# UFS0_P2A_WRAP_CFG_VBP_UFSHCI register map
Vendor: Texas Instruments
Peripheral module from a debugger description file (folder J7ES).
Registers are 32-bit, read-only, reset 0x0 unless marked. A register's access mark holds for its fields unless they carry their own. Offsets are as the file gives them; lines under a group give offsets from that group; [hi:lo] are bit positions; {n}, {i} and the like mark numbered series; 'fields as' and 'values as' point back to an identical list; <NAME> marks a mode.

## UFS0_P2A_WRAP_CFG_VBP_UFSHCI
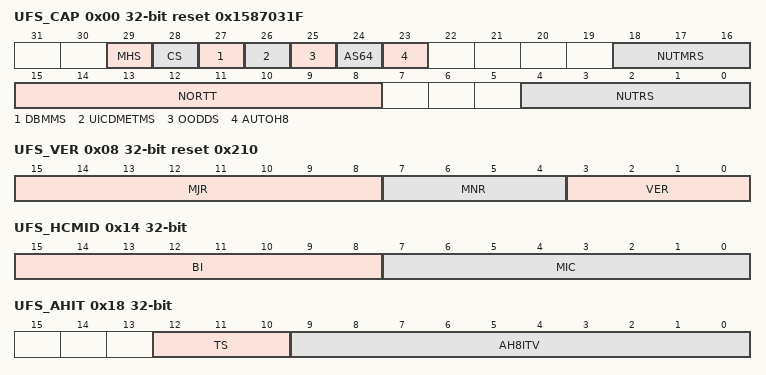
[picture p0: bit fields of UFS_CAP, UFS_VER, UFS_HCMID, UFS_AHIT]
0x00 UFS_CAP reset 0x1587031F — Host Controller Capabilities Register This register describes the basic capabilities of the UFS host controller.
  [29] MHS — Multi-Host Support
  [28] CS — Crypto Support
  [27] DBMMS — Device Bus Master Mode Supported (Unified Memory (UM) UFSHCI Only)
  [26] UICDMETMS — UIC DME_TEST_MODE Command Supported
  [25] OODDS — Out of Order Data Delivery Supported
  [24] AS64 — 64-bit Addressing Supported
  [23] AUTOH8 — Auto-Hibernation Support
  [18:16] NUTMRS — Number of UTP Task Management Request Slots
  [15:8] NORTT — Number of Pending RTTs supported
  [4:0] NUTRS — Number of UTP Transfer Request Slots
0x08 UFS_VER reset 0x210 — UFS Version Register This register indicates the major and minor version of the UFSHCI specification that the controller implementation supports. The upper two bytes represent the major version number, and the lower two bytes represent the minor version number.
  [15:8] MJR — Major Version Number
  [7:4] MNR — Minor Version Number
  [3:0] VER — Version Suffix (VS)
0x10 UFS_HCPID — Host Controller Identification Descriptor Register (Device ID and Device Class) This register indicates the product identification information for host controller.
  [31:0] PID — Product ID
0x14 UFS_HCMID — Host Controller Identification Descriptor Register (Product ID and Manufacturer ID) This register provides Manufacturer identification information for host controller manufacturer. The Manufacturer ID is defined by JEDEC in Standard Manufacturer's identification code (JEDEC-JEP106). The Manufacturer ID consists of two parts: Manufacturer Identification Code and Bank Index.
  [15:8] BI — Bank Index
  [7:0] MIC — Manufacturer Identification Code
0x18 UFS_AHIT access per field — Auto-Hibernate Idle Timer Register The UFS utilizes UniPro and SCSI standards as its power management framework. To improve power efficiency, the UFS host controller may support a mechanism called auto-hibernation. Auto-hibernation allows the host controller to put the UFS link into HIBERN8 state autonomously. The [23] AUTOH8 bit provides a method for software to detect support of this feature. The [9-0] AH8ITV bit filed together with the [12-10] TS bit filed provides a method for software to directly control of this feature. Note: Additionally to the above conditions, the auto-hibernation counter checks the status of the UniPro protocol layer. The host controller will only enter hibernate state when there is no pending UniPro communication.
  [12:10] TS rw — Time Scale
  [9:0] AH8ITV rw — Auto-Hibernate Idle Timer Value
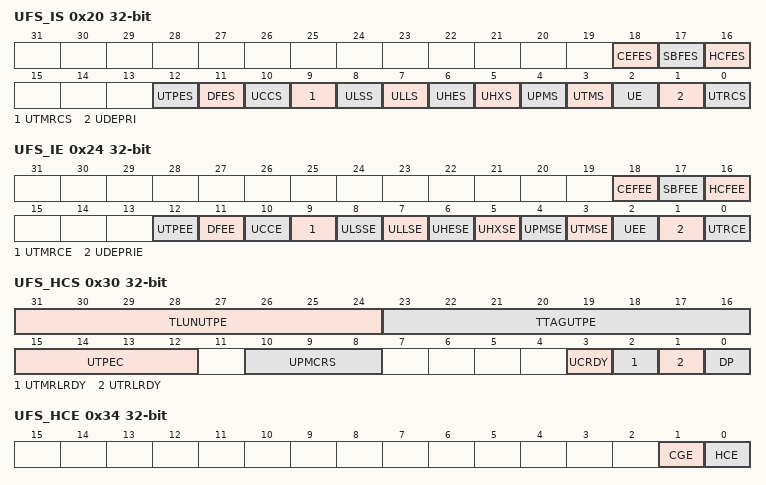
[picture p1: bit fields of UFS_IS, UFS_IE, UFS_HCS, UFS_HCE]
0x20 UFS_IS access not given — Interrupt Status Register This register indicates pending interrupts that require service by the low level driver firmware.
  [18] CEFES — Crypto Engine Fatal Error Status (access RW1C)
  [17] SBFES — System Bus Fatal Error Status (access RW1C)
  [16] HCFES — Host Controller Fatal Error Status (access RW1C)
  [12] UTPES — UTP Error Status (access RW1C)
  [11] DFES — Device Fatal Error Status (access RW1C)
  [10] UCCS — UIC Command Completion Status (access RW1C)
  [9] UTMRCS — UTP Task Management Request Completion Status (access RW1C)
  [8] ULSS — UIC Link Startup Status (access RW1C)
  [7] ULLS — UIC Link Lost Status (access RW1C)
  [6] UHES — UIC Hibernate Enter Status (access RW1C)
  [5] UHXS — UIC Hibernate Exit Status (access RW1C)
  [4] UPMS — UIC Power Mode Status (access RW1C)
  [3] UTMS — UIC Test Mode Status (access RW1C)
  [2] UE — UIC Error (access RW1C)
  [1] UDEPRI — UIC DME_ENDPOINTRESET Indication (access RW1C)
  [0] UTRCS — UTP Transfer Request Completion Status (access RW1C)
0x24 UFS_IE access per field — Interrupt Enable Register This register enables and disables the reporting of the corresponding interrupt to host software. When a bit is set (1h) and the corresponding interrupt condition is active, then an interrupt is generated. Interrupt sources that are disabled (0h) are still indicated in the register. The register bit assignment matches with the register.
  [18] CEFEE rw — Crypto Engine Fatal Error Enable
  [17] SBFEE rw — System Bus Fatal Error Enable
  [16] HCFEE rw — Host Controller Fatal Error Enable
  [12] UTPEE rw — UTP Error Enable
  [11] DFEE rw — Device Fatal Error Enable
  [10] UCCE rw — UIC COMMAND Completion Enable
  [9] UTMRCE rw — UTP Task Management Request Completion Enable
  [8] ULSSE rw — UIC Link Startup Status Enable
  [7] ULLSE rw — UIC Link Lost Status Enable
  [6] UHESE rw — UIC Hibernate Enter Status Enable
  [5] UHXSE rw — UIC Hibernate Exit Status Enable
  [4] UPMSE rw — UIC Power Mode Status Enable
  [3] UTMSE rw — UIC Test Mode Status Enable
  [2] UEE rw — UIC Error Enable
  [1] UDEPRIE rw — UIC DME_ENDPOINTRESET
  [0] UTRCE rw — UTP Transfer Request Completion Enable
0x30 UFS_HCS — Host Controller Status Register The software shall check that the [2] UTMRLRDY bit is set to 1h before issuing a Task Management command. The software shall check that the [1] UTRLRDY bit is set to 1h before issuing an UTP command. The prerequisite to send any DME command is that the [0] HCE and [3] UCRDY bits are set to 1h. The hardware does not check nor restrict the usage of any UIC command. Sending the DME_ENABLE UIC command is not permitted. Additional UIC command specific prerequisites: DME cmd = DME_SET, DP = Don't care, UIC state = Don't care DME cmd = DME_GET, DP = Don't care, UIC state = Don't care DME cmd = DME_PEER_SET, DP = 1, UIC state = LinkUp DME cmd = DME_PEER_GET, DP = 1, UIC state = LinkUp DME cmd = DME_RESET, DP = Don't care, UIC state = Don't care DME cmd = DME_ENPOINTRESET, DP = 1, UIC state = LinkUp DME cmd = DME_LINKSTARTUP, DP = 0, UIC state = LinkDown DME cmd = DME_HIBERNATE_ENTER, DP = Don't care, UIC state = LinkUp, LinkDown DME cmd = DME_HIBERNATE_EXIT, DP = 0, UIC state = Hibernate
  [31:24] TLUNUTPE — Target LUN of UTP Error
  [23:16] TTAGUTPE — Task Tag of UTP Error
  [15:12] UTPEC — UTP Error Code
  [10:8] UPMCRS — UIC Power Mode Change Request Status
  [3] UCRDY — UIC COMMAND Ready
  [2] UTMRLRDY — UTP Task Management Request List Ready
  [1] UTRLRDY — UTP Transfer Request List Ready
  [0] DP — Device Present
0x34 UFS_HCE access per field — Host Controller Enable Register
  [1] CGE rw — Crypto General Enable
  [0] HCE rw — Host Controller Enable
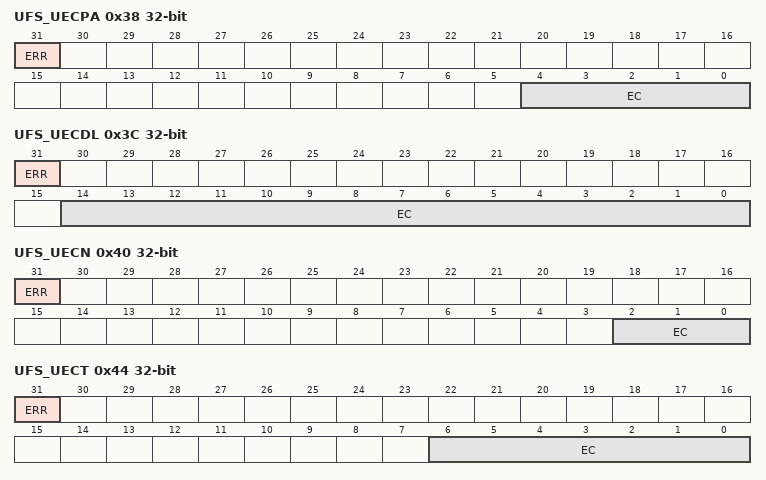
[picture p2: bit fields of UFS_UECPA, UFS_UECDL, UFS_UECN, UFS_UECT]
0x38 UFS_UECPA — Host Controller UIC Error Code PHY Adapter Layer Register Note: The register content is automatically cleared after reading.
  [31] ERR — UIC PHY Adapter Layer Error
  [4:0] EC — UIC Adapter Layer Error
0x3C UFS_UECDL — Host UIC Error Code Data Link Layer Register Note: The register content is automatically cleared after reading.
  [31] ERR — UIC Data Link Layer Error
  [14:0] EC — UIC Data Link Layer Error
0x40 UFS_UECN — Host UIC Error Code Network Layer Register Note: The register content is automatically cleared after reading.
  [31] ERR — UIC Network Layer Error
  [2:0] EC — UIC Network Layer Error Code
0x44 UFS_UECT — Host UIC Error Code Transport Layer Register Note: The register content is automatically cleared after reading.
  [31] ERR — UIC Transport Layer Error
  [6:0] EC — UIC Transport Layer Error Code
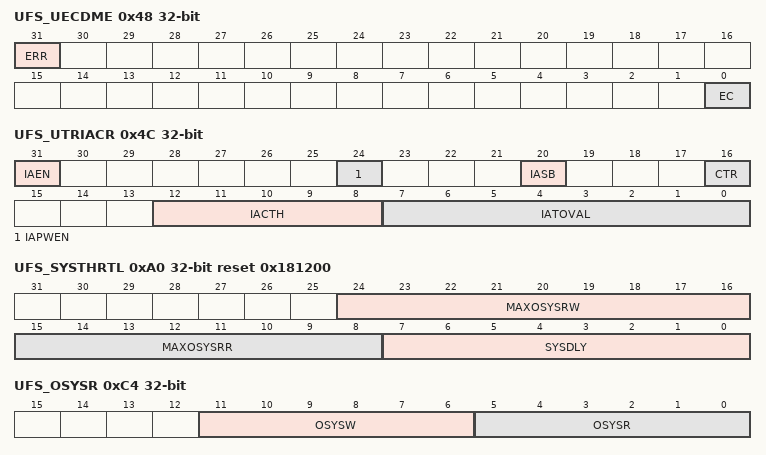
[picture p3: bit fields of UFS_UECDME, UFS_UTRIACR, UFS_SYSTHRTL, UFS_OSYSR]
0x48 UFS_UECDME — Host UIC Error Code DME Register The register is reserved for future use and is fixed to 0000 0000h. Note: The register content is automatically cleared after reading.
  [31] ERR — UIC DME Error
  [0] EC — UIC DME Error Code
0x4C UFS_UTRIACR access per field — UTP Transfer Request Interrupt Aggregation Control Register
  [31] IAEN rw — Interrupt Aggregation Enable/Disable
  [24] IAPWEN rw — Interrupt Aggregation Parameter Write Enable
  [20] IASB ro — Interrupt Aggregation Status Bit
  [16] CTR wo — Counter and Timer Reset
  [12:8] IACTH rw — Interrupt Aggregation Counter Threshold
  [7:0] IATOVAL rw — Interrupt Aggregation Timeout Value
0x50 UFS_UTRLBA access per field — UTP Transfer Request List Base Address Register
  [31:10] UTRLBA rw — UTP Transfer Request List Base Address
0x54 UFS_UTRLBAU rw — UTP Transfer Request List Base Address Upper 32-bits Register Note: Since this UFS host controller implementation supports an 32-bit address bus, the upper 32-bit of the base address are ignored.
  [31:0] UTRLBAU — UTP Transfer Request List Base Address Upper
0x58 UFS_UTRLDBR access not given — UTP Transfer Request List Door Bell Register This register controls the basic actions of the host controller.
  [31:0] UTRLDBR — UTP Transfer Request List Door Bell Register (access RW1S)
0x5C UFS_UTRLCLR wo — UTP Transfer Request List Clear Register
  [31:0] UTRLCLR — UTP Transfer Request List Clear
0x60 UFS_UTRLRSR access per field — UTP Transfer Request List Run Stop Register This register controls the command processing of the UFS host controller.
  [0] UTRLRSR rw — UTP Transfer Request List Run-Stop
0x64 UFS_UTRLCNR access not given — UTP Transfer Request List Completion Notification Register
  [31:0] UTRLCNR — UTP Transfer Request List Completion Notification Register (access RW1C)
0x70 UFS_UTMRLBA access per field — UTP Task Management Request List Base Address
  [31:10] UTMRLBA rw
0x74 UFS_UTMRLBAU rw — UTP Task Management Request List Base Address Upper 32-bits Register Note: This register is only used when the host is configured to use a 64-bit address bus.
  [31:0] UTMRLBAU — UTP Task Management Request List Base Address
0x78 UFS_UTMRLDBR access not given — UTP Task Management Request List Door Bell Register
  [7:0] UTMRLDBR — UTP Task Management Request List Doorbell Register (access RW1S)
0x7C UFS_UTMRLCLR access per field — UTP Task Management Request List Clear Register
  [7:0] UTMRLCLR wo — UTP Task Management List Clear Register
0x80 UFS_UTMRLRSR access per field — - UTP Task Management Request List Run Stop Register
  [0] UTMRLRSR rw — UTP Task Management Request List Run-Stop Register
0x90 UFS_UICCMD access per field — UIC Command Register Sending the DME_ENABLE UIC command is not permitted since this will be done automatically during the UFS host controller initialization.
  [7:0] CMDOP rw — Command Opcode
0x94 UFS_UICCMDARG1 rw — UIC Command Argument 1 Register MIBattribute: Indicates the ID of the attribute of the requested. See MIPI UniPro Specification (UNIPRO) for the details of the MIBattribute parameter. GenSelectorIndex: Indicates the targeted M-PHY data lane or CPort or Test Feature when relevant. See MIPI UniPro Specification (UNIPRO) for the details of the GenSelectorIndex parameter. Layer: L1 - Valid Range: 0 to 2×PA_MaxDataLanes - 1 Layer: L4/Cport - Valid Range: 0 to T_NumCPorts - 1 Layer: L4/Test Feature - Valid Range: 0 to T_NumTestFeatures - 1 ResetLevel: Indicates the reset type. See MIPI UniPro Specification (UNIPRO) for the details of the ResetLevel parameter. 0h - Cold Reset 1h - Warm Reset 2h-FFh - Reserved
  [31:0] ARG1 — UIC Command Argument 1 (MIBattribute, GenSelectorIndex, ResetLevel)
0x98 UFS_UICCMDARG2 rw — UIC Command Argument 2 Register AttrSetType: Indicates whether the attribute value (AttrSet = NORMAL) or the attribute non-volatile reset value (STATIC) setting is requested. See MIPI UniPro Specification (UNIPRO) for the details of the AttrSetType parameter. ConfigResultCode: Indicates the result of the UIC configuration command request. It is valid after host controller has set the [10] UCCS bit to 1h. See MIPI UniPro Specification (UNIPRO) for the details of the ConfigResultCode parameter. 0h = SUCCESS 1h = INVALID_MIB_ATTRIBUTE 2h = INVALID_MIB_ATTRIBUTE_VALUE 3h = READ_ONLY_MIB_ATTRIBUTE 4h = WRITE_ONLY_MIB_ATTRIBUTE 5h = BAD_INDEX 6h = LOCKED_MIB_ATTRIBUTE 7h = BAD_TEST_FEATURE_INDEX 8h = PEER_COMMUNICATION_FAILURE 9h = BUSY Ah = DME_FAILURE Bh-FFh = Reserved GenericErrorCode: Indicates the result of the UIC control command request. It is valid after host controller has set the [10] UCCS bit to 1h. See MIPI UniPro Specification (UNIPRO) for the details of the GenericErrorCode parameter. 0h = SUCCESS 1h = FAILURE 2h-FFh = Reserved
  [31:0] ARG2 — UIC Command Argument 2 (AttrSetType, ConfigResultCode, GenericErrorCode)
0x9C UFS_UICCMDARG3 rw — UIC Command Argument 3 Register MIBvalue_R: Indicates the value of the attribute as returned by the UIC command returned. It is valid after host controller has set the [10] UCCS bit to 1h. See MIPI UniPro Specification (UNIPRO) for the details of the MIBvalue parameter. MIBvalue_W: Indicates the value of the attribute to be set. See MIPI UniPro Specification (UNIPRO) for details of the MIBvalue parameter.
  [31:0] ARG3 — Argument 3
0xA0 UFS_SYSTHRTL access per field reset 0x181200 — SYS Throttling Register In case of heavy data traffic, the UFS host controller might not leave sufficient bandwidth of the OCP/AXI fabric for other peripheral. This register allows throttling the UFS host controller either by limiting the number of outstanding read requests on the OCP/AXI bus or by specifying a minimum delay between two consecutive OCP/AXI accesses. Limiting the number of outstanding requests may also be required in case the bus fabric can only handle a limited amount of requests.
  [24:16] MAXOSYSRW rw — Max Outstanding SYS Write Requests (AXI Only)
  [15:8] MAXOSYSRR rw — Max Outstanding SYS Read Requests
  [7:0] SYSDLY rw — SYS Delay
0xAC UFS_HCI_MMIO_TOSH_UNIRESPOL access per field — UniPro Reset Polling Register
  [0] RESPOL rw — UniPro Reset Polling
0xC4 UFS_OSYSR — Outstanding SYS Requests Register
  [11:6] OSYSW — Outstanding SYS Write Requests
  [5:0] OSYSR — Outstanding SYS Read Requests
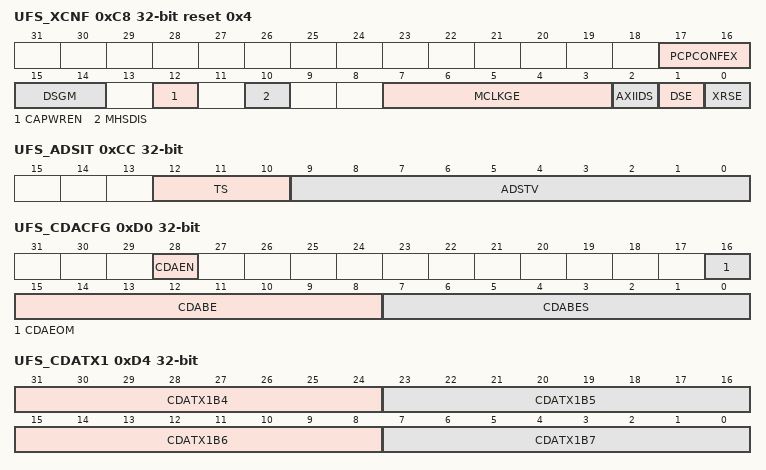
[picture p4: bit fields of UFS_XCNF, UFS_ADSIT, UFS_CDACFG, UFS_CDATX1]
0xC8 UFS_XCNF access per field reset 0x4 — Extended Configuration Register
  [17:16] PCPCONFEX rw — Peer C-Port Configuration Extended
  [15:14] DSGM rw — Deep-Sleep Generation Mode
  [12] CAPWREN rw — Capability Register Write Enable
  [10] MHSDIS rw
  [7:3] MCLKGE rw — Module Clock Gating Enable
  [2] AXIIDS rw — AXI ID support
  [1] DSE rw — Deep Sleep Enable
  [0] XRSE rw — Extended Register Space Enable
0xCC UFS_ADSIT access per field — Auto-Deep-Sleep Idle Timer Register UFS utilizes UniPro and SCSI standards as its power management framework. To improve power efficiency, the UFS host controller may support a mechanism called deep-sleep. Deep-Sleep allows the host controller to put the UFS link into deep-sleep state autonomously. Unlike hibernation, deep-sleep can be entered without input or information from the (UFS) application layer. Thus, deep-sleep is transparent to the UFS software stack. In case, both, Auto-Hibernate and Auto-DeepSleep are both enabled, the Auto Hibernate Time shall be set greater than the Auto DeepSleep Time: [12-10] TS bit filed × [9-0] AH8ITV bit filed greater than [12-10] TS bit filed × [9-0] ADSTV bit filed
  [12:10] TS rw — Time Scale
  [9:0] ADSTV rw — Auto-Deep-Sleep Idle Timer Value
0xD0 UFS_CDACFG access per field — C-Port Direct Access Configuration Register This register configures and manages the basic functionality of this feature. To use this function in a 128-bit system, the IP module provides shadow register for the upper 64 bit data. A write in the following order is required: , CDATX1S, , CDATX2S. For receive data, a read in the following order is required: , CDARX1S, , CDARX2S.
  [28] CDAEN rw — C-Port Direct Access Enable
  [16] CDAEOM rw — C-Port Direct Access
  [15:8] CDABE rw — C-Port Direct Access Byte Enables
  [7:0] CDABES ro — C-Port Direct Access Shadow Byte Enables
0xD4 UFS_CDATX1 rw — C-Port Direct Access Transmit 1 Register This register takes the lower 32 bit of the 64-bit data word to be transferred. In a 128-bit implementation, an additional shadow register is available under the same address. Thus two writes are required to set the lower 64 bit of a received 128-bit word. Note: Since the UIC layer follows big endian byte order, also the and registers follow big endian byte order.
  [63-8n:56-8n] CDATX1B{n} (n=4..7) — CDATX1B
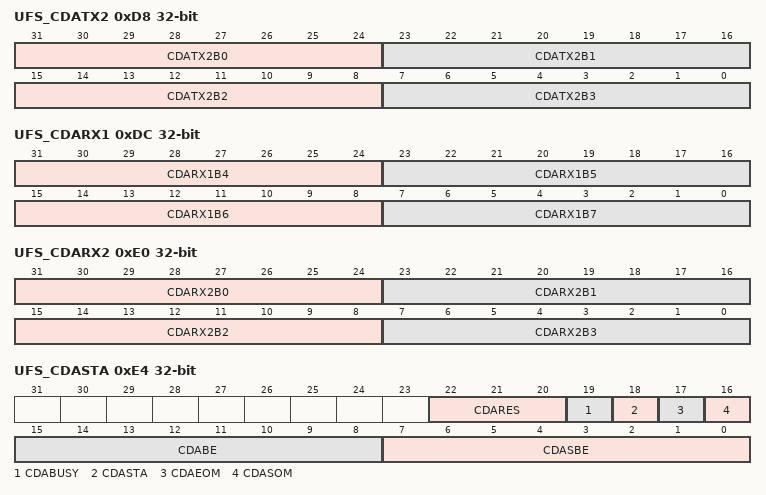
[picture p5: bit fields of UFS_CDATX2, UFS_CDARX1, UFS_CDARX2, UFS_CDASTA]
0xD8 UFS_CDATX2 rw — C-Port Direct Access Transmit 2 Register This register takes the lower 32 bit of the 64-bit data word to be transferred. Writing to this address will push the data to the UniPro adapter. In a 128bit implementation, an additional shadow register is available under the same address. Thus two writes are required to set the lower 64 bit of a received 128-bit word. Note: Since the UIC layer follows big endian byte order, also the and registers follow big endian byte order.
  [31-8n:24-8n] CDATX2B{n} (n=0..3) — CDATX2B
0xDC UFS_CDARX1 — C-Port Direct Access Receive 1 Register This register takes the lower 32 bit of the received 64-bit data word in case of a 64-bit system bus configuration. In a 128-bit implementation, an additional shadow register is available under the same address. Thus two reads are required to get the lower 64 bit of a received 128-bit word. Note: Since the UIC layer follows big endian byte order, also the and registers follow big endian byte order.
  [63-8n:56-8n] CDARX1B{n} (n=4..7) — CDARX1B
0xE0 UFS_CDARX2 — C-Port Direct Access Receive 2 Register This register takes the upper 32 bit of the received 64-bit data word. In a 128-bit implementation, an additional shadow register is available under the same address. Thus two reads are required to get the upper 64 bit of a received 128-bit word. Note: Since the UIC layer follows big endian byte order, also the and registers follow big endian byte order.
  [31-8n:24-8n] CDARX2B{n} (n=0..3) — CDARX2B
0xE4 UFS_CDASTA — C-Port Direct Access Status Register This register contains status information related to the last transfer.
  [22:20] CDARES — C-Port Direct Access Result
  [19] CDABUSY — C-Port Direct Access Busy
  [18] CDASTA — C-Port Direct Access Status
  [17] CDAEOM — C-Port Direct Access EOM
  [16] CDASOM — C-Port Direct Access SOM
  [15:8] CDABE — C-Port Direct Access Byte Enable
  [7:0] CDASBE — C-Port Direct Access Shadow Byte Enable
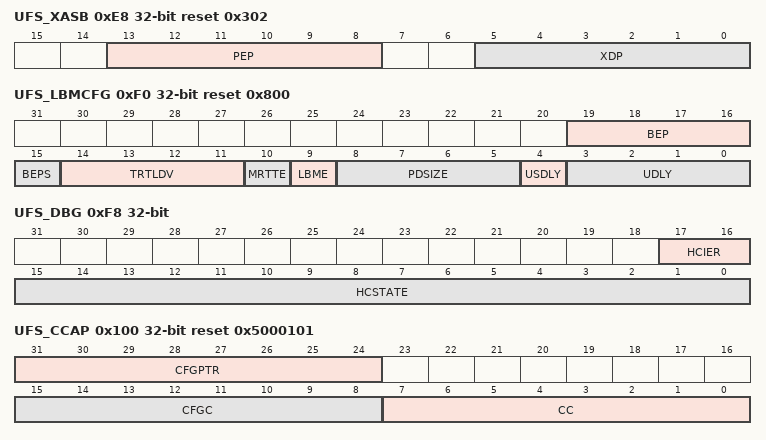
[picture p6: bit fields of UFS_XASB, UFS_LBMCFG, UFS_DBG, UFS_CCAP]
0xE8 UFS_XASB access per field reset 0x302 — Extended Address Space Base Register
  [13:8] PEP rw — Pseudo Error Page
  [5:0] XDP rw — Extended Debug Page
0xF0 UFS_LBMCFG access per field reset 0x800 — UPIU Loopback Configuration Register
  [19:16] BEP rw — Byte Enable Pattern
  [15] BEPS rw — Byte Enable Pattern Selection
  [14:11] TRTLDV rw — Throttle Divide
  [10] MRTTE rw — Multi RTT Enable
  [9] LBME rw — Loopback Enable bit
  [8:5] PDSIZE rw — Data Size
  [4] USDLY rw — UPIU Source Delay
  [3:0] UDLY rw — UPIU Delay
0xF4 UFS_LBMSTA — UPIU Loopback Status Register
  [0] ERR — Error Indicator
0xF8 UFS_DBG — Debug Register
  [17:16] HCIER — Host Controller Internal Error Register
  [15:0] HCSTATE — Host Controller State
0xFC UFS_HCLKDIV access per field reset 0x190 — Host Clock Divider Register Note: This register configures the Tick1us clock required by UniPro. This clock is actually a 500 KHz signal, thus there is one clock edge every 1 µs (rising and falling). This signal is used for UniPro internal counters. The signal is not used as a clock directly. Rather the UniPro logic is doing an edge detection and the signal sampled inside the core. As an alternative the UFSHCI also provides an external input ad a select to provide the signal. From a system's point of view, this signal may be created by the M-PHY logic.
  [15:0] HCLKDIV rw — Host Clock Divide
0x100 UFS_CCAP reset 0x5000101 — Crypto Capabilities Register
  [31:24] CFGPTR — Configuration Array Pointer
  [15:8] CFGC — Configuration Count
  [7:0] CC — Crypto Capabilities
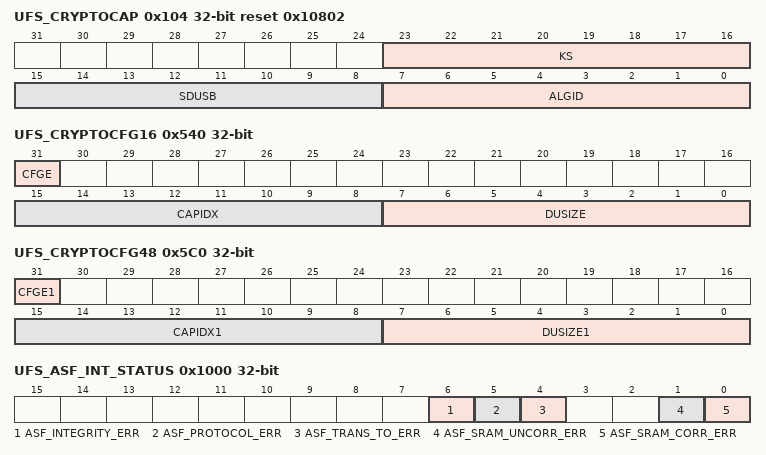
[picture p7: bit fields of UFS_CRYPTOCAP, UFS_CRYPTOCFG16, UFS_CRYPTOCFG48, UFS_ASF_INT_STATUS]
0x104 UFS_CRYPTOCAP reset 0x10802 — Crypto Capability X Register
  [23:16] KS — Key Size
  [15:8] SDUSB — Supported Data Unit Size Bitmask
  [7:0] ALGID — Algorithm
{0x500+4i} UFS_CRYPTOCFG{i} wo (i=0..3) — Crypto Configuration {i} Register
  [31:0] CRYPTOKEY{i}
0x540 UFS_CRYPTOCFG16 access per field — Crypto Configuration 16 Register
  [31] CFGE rw — Configuration Enable
  [15:8] CAPIDX rw — Crypto Capability Index
  [7:0] DUSIZE rw — Data Unit Size
0x544 UFS_CRYPTOCFG17 access per field — Crypto Configuration 17 Register
  [31:16] VSB rw — Vendor-Specific Bits
{0x500+4i} UFS_CRYPTOCFG{i} wo (i=32..35) — Crypto Configuration {i-32} for Second Crypto Configuration Register
  [31:0] CRYPTOKEY{i} — Crypto Key {i-32} for second crypto configuration
0x5C0 UFS_CRYPTOCFG48 access per field — Crypto Configuration 16 for Second Crypto Configuration Register
  [31] CFGE1 rw — Configuration Enable for second crypto configuration
  [15:8] CAPIDX1 rw — Crypto Capability Index for second crypto configuration
  [7:0] DUSIZE1 rw — Data Unit Size for second crypto configuration
0x5C4 UFS_CRYPTOCFG49 access per field — Crypto Configuration 17 for Second Crypto Configuration Register
  [31:16] VSB1 rw — Vendor-Specific Bits for Second Crypto Configuration
0x1000 UFS_ASF_INT_STATUS access not given — ASF Interrupt Status Register This register indicates the source of ASF interrupts. The corresponding bit in the mask register must be clear for a bit to be set. If any bit is set in this register the asf_int_fatal or asf_int_nonfatal signal will be asserted. Writing to either raw or masked status registers, clear both registers. For test purposes, trigger signal interrupt event by writing to the ASF interrupt status test register.
  [6] ASF_INTEGRITY_ERR — Integrity error interrupt (access RW1C)
  [5] ASF_PROTOCOL_ERR — Protocol error interrupt (access RW1C)
  [4] ASF_TRANS_TO_ERR — Transaction timeouts error interrupt (access RW1C)
  [1] ASF_SRAM_UNCORR_ERR — SRAM uncorrectable error interrupt (access RW1C)
  [0] ASF_SRAM_CORR_ERR — SRAM correctable error interrupt (access RW1C)
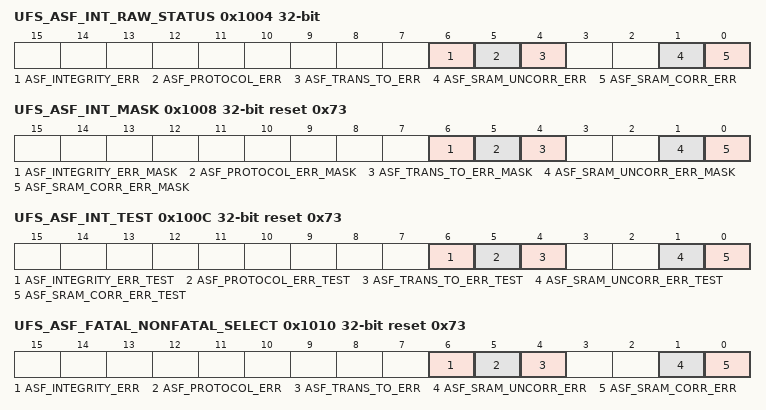
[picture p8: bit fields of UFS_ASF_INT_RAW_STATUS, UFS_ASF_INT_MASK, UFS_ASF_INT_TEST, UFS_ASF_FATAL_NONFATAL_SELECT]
0x1004 UFS_ASF_INT_RAW_STATUS access not given — ASF Interrupt Raw Status Register A bit set in this raw register indicates a source of ASF fault in the corresponding feature. Writing to either raw or masked status registers, clear both registers. For test purposes, trigger signal interrupt event by writing to the ASF interrupt status test register.
  fields as UFS_ASF_INT_STATUS
0x1008 UFS_ASF_INT_MASK access per field reset 0x73 — ASF Interrupt Mask Register The ASF interrupt mask register indicating which interrupt bits in the ASF interrupt status register are masked. All bits are set at reset. Clear the individual bit to enable the corresponding interrupt.
  [6] ASF_INTEGRITY_ERR_MASK rw — Mask bit for integrity error interrupt
  [5] ASF_PROTOCOL_ERR_MASK rw — Mask bit for protocol error interrupt.
  [4] ASF_TRANS_TO_ERR_MASK rw — Mask bit for transaction timeouts error interrupt.
  [1] ASF_SRAM_UNCORR_ERR_MASK rw — Mask bit for SRAM uncorrectable error interrupt.
  [0] ASF_SRAM_CORR_ERR_MASK rw — Mask bit for SRAM correctable error interrupt.
0x100C UFS_ASF_INT_TEST access per field reset 0x73 — ASF Interrupt Test Register The ASF interrupt test register emulate hardware even. Write one to individual bit to trigger single event in (masked and raw) status registers according to mask and will generate interrupt accordingly.
  [6] ASF_INTEGRITY_ERR_TEST wo — Test bit for integrity error interrupt
  [5] ASF_PROTOCOL_ERR_TEST wo — Test bit for protocol error interrupt.
  [4] ASF_TRANS_TO_ERR_TEST wo — Test bit for transaction timeouts error interrupt.
  [1] ASF_SRAM_UNCORR_ERR_TEST wo — Test bit for SRAM uncorrectable error interrupt.
  [0] ASF_SRAM_CORR_ERR_TEST wo — Test bit for SRAM correctable error interrupt.
0x1010 UFS_ASF_FATAL_NONFATAL_SELECT access per field reset 0x73 — Fatal or Non-Fatal Interrupt Register The fatal or non-fatal interrupt register selects whether a fatal (asf_int_fatal) or non-fatal (asf_int_nonfatal) interrupt is triggered. If the bit of the event will be set to one then fatal interrupt (asf_int_fatal) will be triggered. Otherwise the non-fatal interrupt (asf_int_nonfatal) will be triggered.
  [6] ASF_INTEGRITY_ERR rw — Enable integrity error interrupt as fatal
  [5] ASF_PROTOCOL_ERR rw — Enable protocol error interrupt as fatal.
  [4] ASF_TRANS_TO_ERR rw — Enable transaction timeouts error interrupt as fatal.
  [1] ASF_SRAM_UNCORR_ERR rw — Enable SRAM uncorrectable error interrupt as fatal.
  [0] ASF_SRAM_CORR_ERR rw — Enable SRAM correctable error interrupt as fatal.
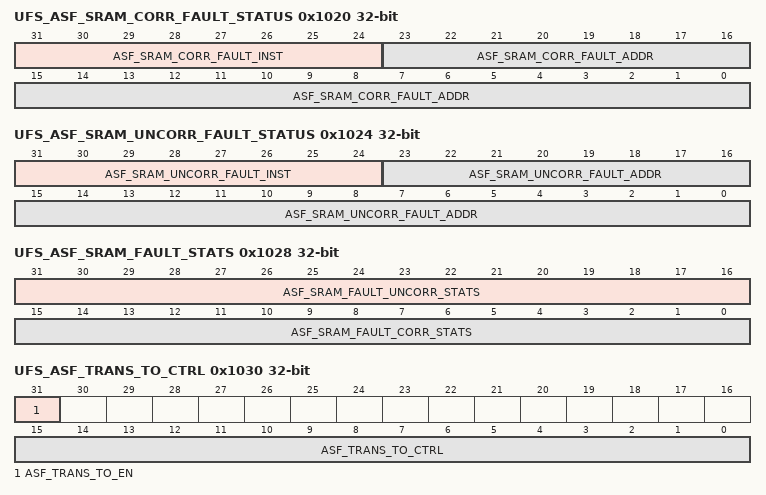
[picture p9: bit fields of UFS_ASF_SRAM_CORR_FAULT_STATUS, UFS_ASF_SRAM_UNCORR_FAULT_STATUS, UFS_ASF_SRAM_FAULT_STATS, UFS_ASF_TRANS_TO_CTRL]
0x1020 UFS_ASF_SRAM_CORR_FAULT_STATUS — Status Register for SRAM Correctable Fault Register This captures all SRAM ECC Correctable Errors. This records the Instance and the address of the first error seen in the SRAM Correctable error.
  [31:24] ASF_SRAM_CORR_FAULT_INST — This encoding indicates which SRAM Instance has a Correctable Fault.
  [23:0] ASF_SRAM_CORR_FAULT_ADDR — This indicates the address where the Correctable fault was observed.
0x1024 UFS_ASF_SRAM_UNCORR_FAULT_STATUS — Status Register (For SRAM Uncorrectable Fault) This captures all SRAM ECC UnCorrectable Errors. Uncorrectable Errors Include both ECC multi bit errors and parity errors found on data and address for SRAM. This records the Instance and the address of the first error seen in the SRAM UnCorrectable error.
  [31:24] ASF_SRAM_UNCORR_FAULT_INST — This encoding indicates which SRAM Instance has a UnCorrectable Fault.
  [23:0] ASF_SRAM_UNCORR_FAULT_ADDR — This indicates the address where the UnCorrectable fault was observed.
0x1028 UFS_ASF_SRAM_FAULT_STATS access not given — Statistics Register (For SRAM Faults) Note that this register clears when software writes to any field.
  [31:16] ASF_SRAM_FAULT_UNCORR_STATS — Count of number of uncorrectable errors if implemented. (access RW1C)
  [15:0] ASF_SRAM_FAULT_CORR_STATS — Count of number of correctable errors if implemented. (access RW1C)
0x1030 UFS_ASF_TRANS_TO_CTRL access per field — Control Register (To Configure The ASF Transaction Timeout Monitors)
  [31] ASF_TRANS_TO_EN rw — Enable transaction timeout monitoring.
  [15:0] ASF_TRANS_TO_CTRL rw — Reserved
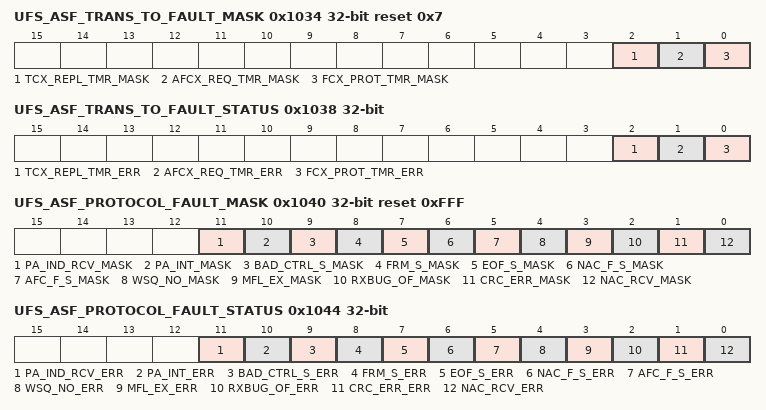
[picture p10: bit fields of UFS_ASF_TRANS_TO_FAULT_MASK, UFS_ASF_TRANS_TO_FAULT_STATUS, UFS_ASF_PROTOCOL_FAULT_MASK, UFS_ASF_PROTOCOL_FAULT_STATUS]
0x1034 UFS_ASF_TRANS_TO_FAULT_MASK access per field reset 0x7 — Control Register (To Mask Out ASF Transaction Timeout Faults From Triggering Interrupts) On reset, all bits are set to mask out all sources. Clear the corresponding bit to enable the interrupt source. The width of this field is parameterizable and the bit definitions are implementation specific.
  [2] TCX_REPL_TMR_MASK rw — TCx_REPLAY_TIMER_EXPIRED mask.
  [1] AFCX_REQ_TMR_MASK rw — AFCx_REQUEST_TIMER_EXPIRED mask.
  [0] FCX_PROT_TMR_MASK rw — FCx_PROTECTION_TIMER_EXPIRED mask.
0x1038 UFS_ASF_TRANS_TO_FAULT_STATUS access not given — Status Register (For Transaction Timeouts Fault) Status register for transaction timeouts fault. If a fault occurs the relevant status bit will be set to 1h. Each bit can be cleared by software writing 1h to each bit.
  [2] TCX_REPL_TMR_ERR — TCx_REPLAY_TIMER_EXPIRED timeout detected. (access RW1C)
  [1] AFCX_REQ_TMR_ERR — AFCx_REQUEST_TIMER_EXPIRED timeout detected. (access RW1C)
  [0] FCX_PROT_TMR_ERR — FCx_PROTECTION_TIMER_EXPIRED timeout detected. (access RW1C)
0x1040 UFS_ASF_PROTOCOL_FAULT_MASK access per field reset 0xFFF — Control Register (To Mask Out ASF Protocol Faults From Triggering Interrupts) On reset, all bits are set to mask out all sources. Clear the corresponding bit to enable the interrupt source. The width of this field is parameterizable and the bit definitions are implementation specific.
  [11] PA_IND_RCV_MASK rw — When set to 1h disables the UniPro PA_ERROR_IND_RECEIVED.
  [10] PA_INT_MASK rw — When set to 1h disables the UniPro PA_INIT_ERROR.
  [9] BAD_CTRL_S_MASK rw — When set to 1h disables the UniPro BAD_CTRL_SYMBOL_TYPE.
  [8] FRM_S_MASK rw — When set to 1h disables the UniPro FRAME_SYNTAX_ERROR.
  [7] EOF_S_MASK rw — When set to 1h disables the UniPro EOF_SYNTAX_ERROR.
  [6] NAC_F_S_MASK rw — When set to 1h disables the UniPro NAC_FRAME_SYNTAX_ERROR.
  [5] AFC_F_S_MASK rw — When set to 1h disables the UniPro AFC_FRAME_SYNTAX_ERROR.
  [4] WSQ_NO_MASK rw — When set to 1h disables the UniPro WRONG_SEQUENCE_NUMBER.
  [3] MFL_EX_MASK rw — When set to 1h disables the UniPro MAX_FRAME_LENGTH_EXCEEDED.
  [2] RXBUG_OF_MASK rw — When set to 1h disables the UniPro RX_BUFFER_OVERFLOW.
  [1] CRC_ERR_MASK rw — When set to 1h disables the UniPro CRC_ERROR.
  [0] NAC_RCV_MASK rw — When set to 1h disables the UniPro NAC_RECEIVED.
0x1044 UFS_ASF_PROTOCOL_FAULT_STATUS access not given — Status Register (For Protocol Faults) If a fault occurs the relevant status bit will be set to 1h. Each bit can be cleared by software writing 1h to each bit.
  [11] PA_IND_RCV_ERR — UniPro PA_ERROR_IND_RECEIVED reported. (access RW1C)
  [10] PA_INT_ERR — UniPro PA_INIT_ERROR reported. (access RW1C)
  [9] BAD_CTRL_S_ERR — UniPro BAD_CTRL_SYMBOL_TYPE reported. (access RW1C)
  [8] FRM_S_ERR — UniPro FRAME_SYNTAX_ERROR reported. (access RW1C)
  [7] EOF_S_ERR — UniPro EOF_SYNTAX_ERROR reported. (access RW1C)
  [6] NAC_F_S_ERR — UniPro NAC_FRAME_SYNTAX_ERROR reported. (access RW1C)
  [5] AFC_F_S_ERR — UniPro AFC_FRAME_SYNTAX_ERROR reported. (access RW1C)
  [4] WSQ_NO_ERR — UniPro WRONG_SEQUENCE_NUMBER reported. (access RW1C)
  [3] MFL_EX_ERR — UniPro MAX_FRAME_LENGTH_EXCEEDED reported. (access RW1C)
  [2] RXBUG_OF_ERR — UniPro RX_BUFFER_OVERFLOW reported. (access RW1C)
  [1] CRC_ERR_ERR — UniPro CRC_ERROR reported. (access RW1C)
  [0] NAC_RCV_ERR — UniPro NAC_RECEIVED reported. (access RW1C)
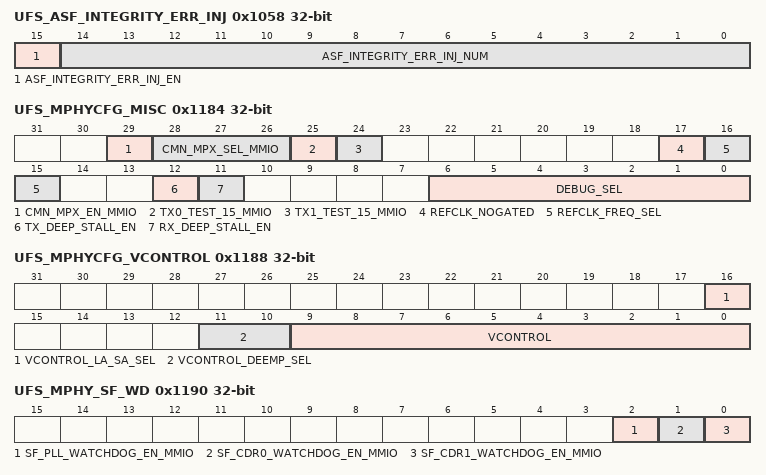
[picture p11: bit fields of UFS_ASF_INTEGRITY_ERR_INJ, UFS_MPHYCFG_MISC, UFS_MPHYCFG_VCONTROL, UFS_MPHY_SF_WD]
0x1058 UFS_ASF_INTEGRITY_ERR_INJ access per field — ASF Integrity Test Register Write one to the enable register inject error to individual n-bit (trigger asf integrity fail to the IP Fault Logging and Reporting module). Please note that only injection error with number to N will generate a fail (i.e. the higher values do not generate fail) where N is the higher value specified in the asf_integrity_err_inj_num field.
  [15] ASF_INTEGRITY_ERR_INJ_EN rw — Enable integrity error injection.
  [14:0] ASF_INTEGRITY_ERR_INJ_NUM rw — Bit number at which error is injected.
0x1100 UFS_MAG_NUM reset 0x5040A — Magic Number Register
  [31:0] MAG_NUM — Magic Number
0x1104 UFS_MPHYSTAT_XCFGO1 — Output Debug Bits For PHY 1 Register
  [31:0] XCFGO1 — Output debug bits for PHY. This field is read only.
{0x1100+4i} UFS_MPHYSTAT_XCFGO{i} (i=2..9) — Output Debug Bits For PHY {i} Register
  [31:0] XCFGO{i} — Output debug bits for PHY. This filed is read only.
0x1128 UFS_MPHY_DEBUG_OUT reset 0x60 — M-PHY Debug Out Register
  [31:0] DEBUG_OUT — MPHY debug out
0x112C UFS_MPHY_BIST — BIST pattern check passed for Lane 0 and Lane 1
  [31:0] MPHY_BIST — BIST pattern check passed for Lane 0 and Lane 1. This field is read only.
0x1130 UFS_MPHY_SF — Safety Register
  [31:0] MPHY_SF — Safety related. This field is read only.
0x1134 UFS_MPHYSTAT — MPHY Status Register
0x1138 UFS_MPHY_MMIO_A access per field — M-PHY Configuration - MMIO Access Register
  [0] MMIO_A rw — This bit is read-write. Enable MPHY MMIO access.
{0x1138+4i} UFS_MPHYCFG_XCFGD{i} rw (i=1..4) — M-PHY Configuration For Digital Part {i} Register
  [31:0] MPHYCFG_XCFGD{i} — This field is read-write. MPHY Configuration for digital part.
0x114C UFS_MPHYCFG_XCFGD5 access per field — M-PHY Configuration For Digital Part 5 Register
  [4:0] MPHYCFG_XCFGD5 rw — This field is read-write. MPHY Configuration for digital part.
{0x114C+4i} UFS_MPHYCFG_XCFGA{i} rw (i=1..13) — M-PHY Configuration For Analog Part {i} Register
  [31:0] MPHYCFG_XCFGA{i} — This field is read-write. MPHY Configuration for analog part.
0x1184 UFS_MPHYCFG_MISC access per field — M-PHY MISC Configuration Register
  [29] CMN_MPX_EN_MMIO rw — Special debug mode for PLL/CDR
  [28:26] CMN_MPX_SEL_MMIO rw — Special debug mode for PLL/CDR
  [25] TX0_TEST_15_MMIO rw — Special debug mode for PLL/CDR
  [24] TX1_TEST_15_MMIO rw — Special debug mode for PLL/CDR
  [17] REFCLK_NOGATED rw — This bit is read-write.
  [16:15] REFCLK_FREQ_SEL rw — This field is read-write.
  [12] TX_DEEP_STALL_EN rw — This bit is read-write.
  [11] RX_DEEP_STALL_EN rw — This bit is read-write.
  [6:0] DEBUG_SEL rw — This field is read-write. Debug signal group selection.
0x1188 UFS_MPHYCFG_VCONTROL access per field — M-PHY VCONTROL Configuration Register
  [16] VCONTROL_LA_SA_SEL rw — This bit is read-write. TX amplitude selection in VENDOR control mode.
  [11:10] VCONTROL_DEEMP_SEL rw — This field is read-write. TX deemphasis selection in VENDOR control mode.
  [9:0] VCONTROL rw — This field is read-write. VCONTROL test mode selection.
0x118C UFS_MPHY_BIST_CTRLPIN rw — M-PHY BIST Control Pins Register
  [31:0] MPHY_BIST_CTRLPIN — This field is read-write.
0x1190 UFS_MPHY_SF_WD access per field — M-PHY Safety Related Watch Dog Register
  [2] SF_PLL_WATCHDOG_EN_MMIO rw — This bit is read-write.
  [1] SF_CDR0_WATCHDOG_EN_MMIO rw — This bit is read-write
  [0] SF_CDR1_WATCHDOG_EN_MMIO rw — This bit is read-write
